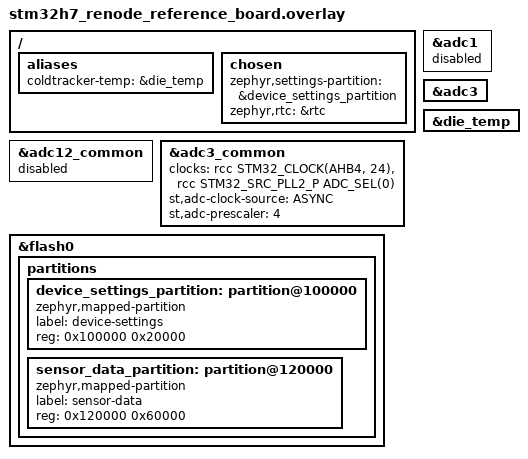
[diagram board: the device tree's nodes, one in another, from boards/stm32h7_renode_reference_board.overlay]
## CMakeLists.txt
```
# SPDX-License-Identifier: Apache-2.0

cmake_minimum_required(VERSION 3.20.0)

list(APPEND SNIPPET_ROOT ${CMAKE_CURRENT_SOURCE_DIR})

find_package(Zephyr REQUIRED HINTS $ENV{ZEPHYR_BASE})

project(cold-tracker)

if (CONFIG_USB_DEVICE_STACK_NEXT)
  include(${ZEPHYR_BASE}/samples/subsys/usb/common/common.cmake)
endif()

target_include_directories(app PRIVATE
  include
)

target_sources(app PRIVATE
  src/main.cpp
  src/coldtracker_sensing.cpp
  src/coldtracker_storage.cpp
  src/coldtracker_faults.cpp
)

target_sources_ifdef(CONFIG_NETWORKING app PRIVATE
  src/coldtracker_network.cpp
  src/network_backend.cpp
  src/coldtracker_time.cpp
  src/coldtracker_telemetry.cpp
)

target_sources_ifdef(CONFIG_BOOTLOADER_MCUBOOT app PRIVATE
  src/coldtracker_ota.cpp
)

if(NOT CONFIG_BOARD_NATIVE_SIM)
  target_sources(app PRIVATE
    # src/heap_trap.cpp
  )
endif()
```

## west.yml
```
manifest:
  version: 0.7

  defaults:
    remote: zephyrproject

  remotes:
    - name: zephyrproject
      url-base: https://github.com/zephyrproject-rtos

    - name: servz
      url-base: https://github.com/bayrem-gharsellaoui

  projects:
    - name: zephyr
      repo-path: zephyr
      revision: main
      path: zephyr
      import:
        name-allowlist:
          - cmsis_6
          - hal_stm32
          - hal_espressif
          - mcuboot
          - mbedtls
          - tf-psa-crypto
          - segger

    - name: servz
      remote: servz
      revision: main
      path: modules/servz

  self:
    path: application
```

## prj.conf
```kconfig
# Logging
CONFIG_LOG=y
CONFIG_LOG_INFO_COLOR_GREEN=y
CONFIG_LOG_DBG_COLOR_BLUE=y

# Shell
CONFIG_SHELL=y
CONFIG_KERNEL_SHELL=y
CONFIG_REBOOT=y

# Sensor
# ADC
CONFIG_ADC=y
CONFIG_SENSOR=y
CONFIG_SENSOR_SHELL=y

# Storage
CONFIG_FLASH=y
CONFIG_FLASH_MAP=y
CONFIG_FCB=y

# C++
CONFIG_CPP=y
CONFIG_STD_CPP17=y
CONFIG_CPP_EXCEPTIONS=n
CONFIG_CPP_RTTI=n

# No heap
CONFIG_HEAP_MEM_POOL_SIZE=0

# servz
CONFIG_SERVZ=y
CONFIG_SERVZ_LOG_LEVEL_DBG=y

# Debugging
CONFIG_DEBUG=y
CONFIG_DEBUG_THREAD_INFO=y
CONFIG_NO_OPTIMIZATIONS=y
CONFIG_SIZE_OPTIMIZATIONS=n
CONFIG_COMPILER_WARNINGS_AS_ERRORS=y
```

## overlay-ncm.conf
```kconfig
# USB device
CONFIG_USB_DEVICE_STACK_NEXT=y

CONFIG_SAMPLE_USBD_MANUFACTURER="Techleef"
CONFIG_SAMPLE_USBD_PRODUCT="ColdTracker"
CONFIG_SAMPLE_USBD_PID=0x0001

# CDC NCM Ethernet
CONFIG_NET_L2_ETHERNET=y

# Networking starts after the USB device is enabled
CONFIG_NET_CONFIG_AUTO_INIT=n
CONFIG_NET_DHCPV4=y

# Keep USB logs quiet
CONFIG_USBD_CDC_NCM_LOG_LEVEL_WRN=y
CONFIG_USBD_LOG_LEVEL_WRN=y
```

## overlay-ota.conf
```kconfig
# OTA
CONFIG_IMG_MANAGER=y
CONFIG_IMG_BLOCK_BUF_SIZE=512
CONFIG_IMG_ENABLE_IMAGE_CHECK=y
CONFIG_IMG_ERASE_PROGRESSIVELY=y
CONFIG_USE_DT_CODE_PARTITION=y

# URL parsing for firmware download URLs
CONFIG_HTTP_PARSER_URL=y

# Flash
CONFIG_FLASH=y
CONFIG_FLASH_MAP=y
CONFIG_FLASH_PAGE_LAYOUT=y
CONFIG_STREAM_FLASH=y
CONFIG_MPU_ALLOW_FLASH_WRITE=y

# Bootloader
CONFIG_MCUBOOT_SHELL=y
```

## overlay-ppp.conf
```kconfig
# PPP over UART
CONFIG_NET_L2_PPP=y
CONFIG_NET_PPP=y
CONFIG_NET_DEFAULT_IF_PPP=y

# Obtain DNS server through IPCP
CONFIG_NET_L2_PPP_OPTION_DNS_USE=y

# UART is dedicated to PPP
CONFIG_UART_CONSOLE=n
CONFIG_SHELL_BACKEND_SERIAL=n
CONFIG_UART_INTERRUPT_DRIVEN=y

# PPP buffers for high baud rates
CONFIG_NET_PPP_UART_BUF_LEN=128
CONFIG_NET_PPP_RINGBUF_SIZE=2048
CONFIG_NET_PPP_RX_STACK_SIZE=2048
```

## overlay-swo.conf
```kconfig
# Logging over ITM/SWO
CONFIG_LOG_BACKEND_SWO=y
CONFIG_LOG_BACKEND_SWO_FREQ_HZ=2000000
CONFIG_LOG_BACKEND_UART=n

# Route printk() through the logging subsystem
CONFIG_LOG_PRINTK=y
```

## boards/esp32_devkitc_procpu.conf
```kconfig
# WiFi
CONFIG_WIFI=y
CONFIG_WIFI_ESP32=y

# Networking
CONFIG_NET_DHCPV4=y

# Stack Sizes
CONFIG_MAIN_STACK_SIZE=4096
CONFIG_SHELL_STACK_SIZE=4096
CONFIG_SYSTEM_WORKQUEUE_STACK_SIZE=4096
CONFIG_ISR_STACK_SIZE=4096
CONFIG_NET_TCP_WORKQ_STACK_SIZE=4096
CONFIG_NET_SOCKETS_SERVICE_STACK_SIZE=4096
CONFIG_NET_CONNECTION_MANAGER_MONITOR_STACK_SIZE=4096
CONFIG_SHELL_BACKEND_SERIAL_LOG_MESSAGE_QUEUE_SIZE=4096
CONFIG_LOG_BUFFER_SIZE=4096

# Debugging
CONFIG_DEBUG_COREDUMP=y
```

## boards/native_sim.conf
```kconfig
# Binary name
CONFIG_KERNEL_BIN_NAME="coldtracker-native_sim"

# Shell/logging on stdin/stdout
CONFIG_UART_NATIVE_PTY_0_ON_STDINOUT=y
CONFIG_SHELL_LOG_BACKEND=n
CONFIG_LOG_RUNTIME_DEFAULT_LEVEL=4

# Sensor
CONFIG_NATIVE_LINUX_TEMP=y

# Posix
CONFIG_POSIX_API=y
```

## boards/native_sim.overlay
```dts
/ {
	aliases {
		coldtracker-temp = &linux_temp;
	};

    chosen {
        zephyr,settings-partition = &device_settings_partition;
		zephyr,rtc = &rtc;
    };

	linux_temp: linux_temp {
		compatible = "zephyr,native-linux-temp";
		path = "/sys/class/hwmon/hwmon6/temp1_input";
		status = "okay";
	};
};

&flash0 {
    partitions {
        /* Disable scratch original partition */
        scratch_partition: partition@de000 {
            status = "disabled";
        };

        /* Disable storage original partition */
        storage_partition: partition@fc000 {
            status = "disabled";
        };

        /* For Settings (device config) - 16 KB = 4 erase blocks */
        device_settings_partition: partition@de000 {
            compatible = "zephyr,mapped-partition";
            label = "device-settings";
            reg = <0xde000 0x4000>;
        };

        /* For FCB sensor data - 120 KB = 30 erase blocks */
        sensor_data_partition: partition@e2000 {
            compatible = "zephyr,mapped-partition";
            label = "sensor-data";
            reg = <0xe2000 0x1e000>;
        };
    };
};
```

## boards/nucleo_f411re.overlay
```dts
/ {
    chosen {
        zephyr,ppp-uart = &usart2;
    };
};

&usart2 {
    current-speed = <921600>;
};
```

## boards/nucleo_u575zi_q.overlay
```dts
/ {
	aliases {
		coldtracker-temp = &die_temp;
	};

	chosen {
		zephyr,settings-partition = &device_settings_partition;
        zephyr,rtc = &rtc;
	};
};

&flash0 {
	partitions {
		/* Disable the old storage_partition */
		storage_partition: partition@1e0000 {
			status = "disabled";
		};

		/* For Settings (device config) - 16 KB = 2 erase blocks */
		device_settings_partition: partition@1e0000 {
			compatible = "zephyr,mapped-partition";
			label = "device-settings";
			reg = <0x1e0000 0x4000>;
		};

		/* For FCB sensor data - 112 KB = 14 erase blocks */
		sensor_data_partition: partition@1e4000 {
			compatible = "zephyr,mapped-partition";
			label = "sensor-data";
			reg = <0x1e4000 0x1c000>;
		};
	};
};
```

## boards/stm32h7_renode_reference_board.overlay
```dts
/ {
	aliases {
		coldtracker-temp = &die_temp;
	};

	chosen {
		zephyr,settings-partition = &device_settings_partition;
		zephyr,rtc = &rtc;
	};
};

&adc1 {
	status = "disabled";
};

&adc12_common {
	status = "disabled";
};

&adc3_common {
	clocks = <&rcc STM32_CLOCK(AHB4, 24)>, <&rcc STM32_SRC_PLL2_P ADC_SEL(0)>;
	clock-names = "adcx", "adc_ker";

	st,adc-clock-source = "ASYNC";
	st,adc-prescaler = <4>;

	status = "okay";
};

&adc3 {
	status = "okay";
};

&die_temp {
	status = "okay";
};

&flash0 {
	partitions {
		/*
		 * Internal flash after MCUboot + slot0 + slot1.
		 *
		 * Board layout ends slot1 at 0x100000.
		 */

		/* 128 KB for settings. */
		device_settings_partition: partition@100000 {
			compatible = "zephyr,mapped-partition";
			label = "device-settings";
			reg = <0x100000 0x20000>;
		};

		/* 384 KB for ColdTracker sensor data. */
		sensor_data_partition: partition@120000 {
			compatible = "zephyr,mapped-partition";
			label = "sensor-data";
			reg = <0x120000 0x60000>;
		};
	};
};
```

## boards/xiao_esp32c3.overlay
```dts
/ {
	aliases {
		coldtracker-temp = &coretemp;
	};

	chosen {
		zephyr,settings-partition = &device_settings_partition;
		zephyr,rtc = &counter_rtc;
	};
};

&coretemp {
	status = "okay";
};

&flash0 {
	partitions {
		/* Disable the old storage_partition */
		storage_partition: partition@3b0000 {
			status = "disabled";
		};

		/* For Settings (device config) - 16 KB = 4 erase blocks */
		device_settings_partition: partition@3b0000 {
			compatible = "zephyr,mapped-partition";
			label = "device-settings";
			reg = <0x3b0000 0x4000>;
		};

		/* For FCB sensor data - 176 KB = 44 erase blocks */
		sensor_data_partition: partition@3b4000 {
			compatible = "zephyr,mapped-partition";
			label = "sensor-data";
			reg = <0x3b4000 0x2c000>;
		};
	};
};

/* Enable the underlying ESP32 RTC timer and attach the virtual RTC child node */
&rtc_timer {
	status = "okay";

	counter_rtc: counter-rtc {
		compatible = "zephyr,rtc-counter";
		status = "okay";
		alarms-count = <0>;
	};
};
```

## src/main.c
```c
#include <zephyr/kernel.h>
#include <zephyr/sys/printk.h>
#include <zephyr/app_version.h>

#define ANSI_COLOR_CYAN  "\033[96m"
#define ANSI_COLOR_GREEN "\033[92m"
#define ANSI_COLOR_RESET "\033[0m"

/* Generated from
 * https://patorjk.com/software/taag/#p=display&f=ANSI+Shadow&t=Type+Something+&x=none&v=4&h=4&w=80&we=false
 * and formatted using "clang-format --style=file:${ZEPHYR_BASE}/.clang-format -i src/main.c"
 */
#define COLDTRACKER_BOOT_BANNER                                                                    \
	"\r\n" ANSI_COLOR_CYAN " ██████╗ ██████╗ ██╗     ██████╗ " ANSI_COLOR_GREEN                \
	"████████╗██████╗  █████╗  ██████╗██╗  ██╗███████╗██████╗ " ANSI_COLOR_RESET               \
	"\r\n" ANSI_COLOR_CYAN "██╔════╝██╔═══██╗██║     ██╔══██╗" ANSI_COLOR_GREEN                \
	"╚══██╔══╝██╔══██╗██╔══██╗██╔════╝██║ ██╔╝██╔════╝██╔══██╗" ANSI_COLOR_RESET               \
	"\r\n" ANSI_COLOR_CYAN "██║     ██║   ██║██║     ██║  ██║" ANSI_COLOR_GREEN                \
	"   ██║   ██████╔╝███████║██║     █████╔╝ █████╗  ██████╔╝" ANSI_COLOR_RESET               \
	"\r\n" ANSI_COLOR_CYAN "██║     ██║   ██║██║     ██║  ██║" ANSI_COLOR_GREEN                \
	"   ██║   ██╔══██╗██╔══██║██║     ██╔═██╗ ██╔══╝  ██╔══██╗" ANSI_COLOR_RESET               \
	"\r\n" ANSI_COLOR_CYAN "╚██████╗╚██████╔╝███████╗██████╔╝" ANSI_COLOR_GREEN                \
	"   ██║   ██║  ██║██║  ██║╚██████╗██║  ██╗███████╗██║  ██║" ANSI_COLOR_RESET               \
	"\r\n" ANSI_COLOR_CYAN " ╚═════╝ ╚═════╝ ╚══════╝╚═════╝ " ANSI_COLOR_GREEN                \
	"   ╚═╝   ╚═╝  ╚═╝╚═╝  ╚═╝ ╚═════╝╚═╝  ╚═╝╚══════╝╚═╝  ╚═╝" ANSI_COLOR_RESET "\r\n"        \
	"\r\n" ANSI_COLOR_GREEN "                     v%s - (c) 2026 Techleef. All rights "        \
	"reserved.\r\n" ANSI_COLOR_RESET ANSI_COLOR_CYAN                                           \
	"                            Target: %s\r\n\r\n" ANSI_COLOR_RESET

int main(void)
{
	printk(COLDTRACKER_BOOT_BANNER, APP_VERSION_STRING, CONFIG_BOARD_TARGET);

	while (1) {
		k_msleep(1000);
	}

	return 0;
}
```

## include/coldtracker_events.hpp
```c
/*
 * Copyright (c) 2026 Bayrem Gharsellaoui
 * SPDX-License-Identifier: Apache-2.0
 */

#pragma once

#include <servz/event.hpp>

enum class Event : servz::EventId {
	NetworkL4Connected,
	NetworkL4Disconnected,
	NetworkConnecting,
	NetworkOnline,
	NetworkOffline,

	TimeSyncRetry,
	TimeAvailableRtc,
	TimeAvailableSntp,

	SensingTick,
	SampleStored,

	TelemetryTick,

	OtaUpdateAvailable,
	OtaUpdateCompleted,
	OtaUpdateFailed,

	Count,
};

static_assert(static_cast<servz::EventId>(Event::Count) <= 32);
```

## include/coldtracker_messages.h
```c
#ifndef COLDTRACKER_MESSAGES_H_
#define COLDTRACKER_MESSAGES_H_

#include <stdbool.h>

#include <zephyr/zbus/zbus.h>

#define NETWORK_STATUS_CHAN_ID 0x1001
#define TIME_STATUS_CHAN_ID    0x1002

enum network_state {
	NETWORK_STATE_OFFLINE = 0,
	NETWORK_STATE_CONNECTING,
	NETWORK_STATE_ONLINE,
};

struct network_status_msg {
	enum network_state state;
};

enum time_state {
	TIME_STATE_UNAVAILABLE = 0,
	TIME_STATE_AVAILABLE,
};

enum time_source {
	TIME_SOURCE_NONE = 0,
	TIME_SOURCE_RTC,
	TIME_SOURCE_SNTP,
};

struct time_status_msg {
	enum time_state state;
	enum time_source source;
};

ZBUS_CHAN_DECLARE(network_status_chan, time_status_chan);

#endif /* COLDTRACKER_MESSAGES_H_ */
```

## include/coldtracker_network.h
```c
#ifndef COLDTRACKER_NETWORK_H_
#define COLDTRACKER_NETWORK_H_

int network_connect(void);
void network_wait_ready(void);

#endif /* COLDTRACKER_NETWORK_H_ */
```

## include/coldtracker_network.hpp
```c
/*
 * Copyright (c) 2026 Bayrem Gharsellaoui
 * SPDX-License-Identifier: Apache-2.0
 */

#pragma once

#include "coldtracker_events.hpp"
#include "network_backend.hpp"

#include <servz/service.hpp>

#include <zephyr/net/net_mgmt.h>

/**
 * @brief Service responsible for managing ColdTracker network connectivity.
 *
 * The service starts the configured network backend and translates Zephyr
 * network management events into application-level servz events.
 */
class NetworkService final: public servz::Service
{
public:
	/**
	 * @brief Construct the network service.
	 *
	 * @param name Service name.
	 * @param event_queue Service event queue.
	 */
	NetworkService(const char *name, struct k_msgq &event_queue);

protected:
	/**
	 * @brief Initialize network monitoring and start the network backend.
	 */
	void on_start() override;

	/**
	 * @brief Handle network events delivered to the service.
	 *
	 * @param event Event identifier.
	 */
	void on_event(servz::EventId event) override;

private:
	/**
	 * @brief Handle Zephyr L4 network state changes.
	 *
	 * @param cb Network management callback.
	 * @param event Network management event.
	 * @param iface Network interface associated with the event.
	 */
	static void l4_event_handler(struct net_mgmt_event_callback *cb, uint64_t event,
				     struct net_if *iface);

	/**
	 * @brief Handle an asynchronous backend connection failure.
	 */
	static void backend_connection_failed();

	static constexpr auto kSubscriptions =
		servz::EventMask::of(Event::NetworkL4Connected, Event::NetworkL4Disconnected);

	struct net_mgmt_event_callback m_l4_mgmt_cb{};
	NetworkBackend m_backend;
};
```

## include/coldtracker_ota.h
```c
#ifndef COLDTRACKER_OTA_H_
#define COLDTRACKER_OTA_H_

int ota_update(const char *url);

#endif /* COLDTRACKER_OTA_H_ */
```

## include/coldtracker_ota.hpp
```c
/*
 * Copyright (c) 2026 Bayrem Gharsellaoui
 * SPDX-License-Identifier: Apache-2.0
 */

#pragma once

#include "coldtracker_events.hpp"

#include <servz/service.hpp>

/**
 * @brief Service responsible for OTA update management.
 *
 * The service waits for network connectivity and checks whether a firmware
 * update is available.
 */
class OtaService final: public servz::Service
{
public:
	/**
	 * @brief Construct the OTA service.
	 *
	 * @param name Service name.
	 * @param event_queue Service event queue.
	 */
	OtaService(const char *name, struct k_msgq &event_queue);

protected:
	/**
	 * @brief Handle events delivered to the OTA service.
	 *
	 * @param event Event identifier.
	 */
	void on_event(servz::EventId event) override;

private:
	/**
	 * @brief Check whether a firmware update is available.
	 */
	void check_for_update();

	static constexpr auto kSubscriptions = servz::EventMask::of(Event::NetworkOnline);
};
```

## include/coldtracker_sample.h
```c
#ifndef COLDTRACKER_SAMPLE_H_
#define COLDTRACKER_SAMPLE_H_

#include <stdint.h>

struct coldtracker_sample {
	int64_t timestamp;
	int32_t temperature_mc;
};

#endif /* COLDTRACKER_SAMPLE_H_ */
```

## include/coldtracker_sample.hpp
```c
/*
 * Copyright (c) 2026 Bayrem Gharsellaoui
 * SPDX-License-Identifier: Apache-2.0
 */

#pragma once

#include <cstdint>

/**
 * @brief ColdTracker temperature sample.
 */
struct ColdTrackerSample {
	std::int64_t timestamp{};
	std::int32_t temperature_mc{};
};
```

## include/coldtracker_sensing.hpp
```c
/*
 * Copyright (c) 2026 Bayrem Gharsellaoui
 * SPDX-License-Identifier: Apache-2.0
 */

#pragma once

#include "coldtracker_events.hpp"
#include "coldtracker_sample.hpp"

#include <servz/service.hpp>

#include <zephyr/device.h>
#include <zephyr/kernel.h>

/**
 * @brief Service responsible for acquiring temperature samples.
 *
 * Sampling starts once valid system time becomes available. Samples are
 * periodically timestamped and written to storage.
 */
class SensingService final: public servz::Service
{
public:
	/**
	 * @brief Construct the sensing service.
	 *
	 * @param name Service name.
	 * @param event_queue Service event queue.
	 */
	SensingService(const char *name, struct k_msgq &event_queue);

protected:
	/**
	 * @brief Initialize the temperature sensor and sampling timer.
	 */
	void on_start() override;

	/**
	 * @brief Handle time availability and sampling events.
	 *
	 * @param event Event identifier.
	 */
	void on_event(servz::EventId event) override;

private:
	/**
	 * @brief Acquire and timestamp one temperature sample.
	 *
	 * @param sample Destination sample.
	 *
	 * @return 0 on success, otherwise a negative errno value.
	 */
	int take_sample(struct ColdTrackerSample &sample);

	/**
	 * @brief Start periodic sensing.
	 */
	void start_sensing();

	/**
	 * @brief Handle expiration of the sensing timer.
	 *
	 * @param timer Sensing timer.
	 */
	static void timer_handler(struct k_timer *timer);

	static constexpr auto kSubscriptions =
		servz::EventMask::of(Event::TimeAvailableRtc, Event::TimeAvailableSntp);

	const struct device *m_sensor;
	struct k_timer m_timer{};
	bool m_started{};
	int m_remaining_samples{3};
};
```

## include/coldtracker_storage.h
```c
#ifndef COLDTRACKER_STORAGE_H_
#define COLDTRACKER_STORAGE_H_

#include "coldtracker_sample.h"

typedef int (*storage_callback_t)(const struct coldtracker_sample *sample, void *user_data);

int storage_foreach(storage_callback_t callback, void *user_data);

int storage_append(const struct coldtracker_sample *sample);

int storage_peek(struct coldtracker_sample *sample);

int storage_commit(void);

#endif /* COLDTRACKER_STORAGE_H_ */
```

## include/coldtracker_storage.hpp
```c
/*
 * Copyright (c) 2026 Bayrem Gharsellaoui
 * SPDX-License-Identifier: Apache-2.0
 */

#pragma once

#include "coldtracker_sample.hpp"

namespace coldtracker::storage
{

/**
 * @brief Callback invoked for each stored sample.
 *
 * @param sample Stored sample.
 * @param user_data User-provided callback context.
 *
 * @return 0 to continue iteration, otherwise a non-zero value to stop.
 */
using Callback = int (*)(const struct ColdTrackerSample &sample, void *user_data);

/**
 * @brief Iterate over all stored samples.
 *
 * @param callback Callback invoked for each sample.
 * @param user_data User-provided callback context.
 *
 * @return 0 on success, otherwise a negative errno value.
 */
int foreach(Callback callback, void *user_data = nullptr);

/**
 * @brief Append a sample to persistent storage.
 *
 * @param sample Sample to store.
 *
 * @return 0 on success, otherwise a negative errno value.
 */
int append(const struct ColdTrackerSample &sample);

/**
 * @brief Read the current uncommitted sample.
 *
 * Calling this function does not remove or advance the stored sample.
 *
 * @param sample Destination sample.
 *
 * @return 0 on success, otherwise a negative errno value.
 */
int peek(struct ColdTrackerSample &sample);

/**
 * @brief Commit the current sample and advance the read cursor.
 *
 * @return 0 on success, otherwise a negative errno value.
 */
int commit();

} // namespace coldtracker::storage
```

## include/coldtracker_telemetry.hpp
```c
/*
 * Copyright (c) 2026 Bayrem Gharsellaoui
 * SPDX-License-Identifier: Apache-2.0
 */

#pragma once

#include "coldtracker_events.hpp"
#include "coldtracker_sample.hpp"

#include <servz/service.hpp>

#include <zephyr/kernel.h>

/**
 * @brief Service responsible for sending stored telemetry data.
 *
 * Pending samples are sent while network connectivity is available. Samples
 * are committed from storage only after they are successfully transmitted.
 */
class TelemetryService final: public servz::Service
{
public:
	/**
	 * @brief Construct the telemetry service.
	 *
	 * @param name Service name.
	 * @param event_queue Service event queue.
	 */
	TelemetryService(const char *name, struct k_msgq &event_queue);

protected:
	/**
	 * @brief Initialize telemetry processing.
	 */
	void on_start() override;

	/**
	 * @brief Handle network, storage, and telemetry events.
	 *
	 * @param event Event identifier.
	 */
	void on_event(servz::EventId event) override;

private:
	/**
	 * @brief Process the next pending telemetry sample.
	 */
	void process_pending();

	/**
	 * @brief Push one sample to the remote telemetry endpoint.
	 *
	 * @param sample Sample to send.
	 *
	 * @return 0 on success, otherwise a negative errno value.
	 */
	int push_sample(const struct ColdTrackerSample &sample);

	/**
	 * @brief Handle expiration of the telemetry timer.
	 *
	 * @param timer Telemetry timer.
	 */
	static void timer_handler(struct k_timer *timer);

	static constexpr auto kSubscriptions = servz::EventMask::of(
		Event::NetworkOnline, Event::NetworkOffline, Event::SampleStored);

	struct k_timer m_timer{};
	bool m_network_online{};
	bool m_processing{};
};
```
